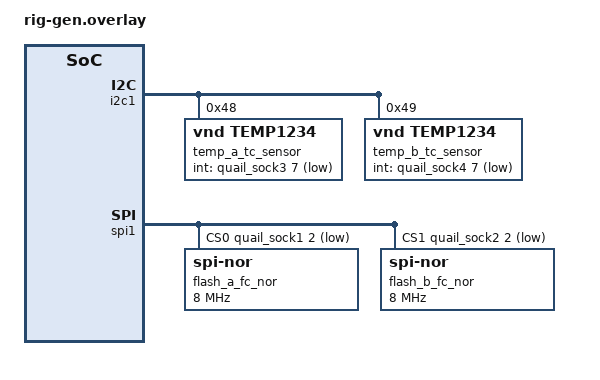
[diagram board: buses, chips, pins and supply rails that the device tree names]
/* generated by rigexp — do not edit; the rig file is the source of truth (R3)
 * rig: quail_temp_farm  board: mikroe_quail/stm32f427xx/rig
 */

&i2c1 {
	temp_a_tc_sensor: sensor@48 {
		compatible = "vnd,temp1234";
		reg = <0x48>;
		int-gpios = <&quail_sock3 7 0x1>;	/* INT */
		status = "okay";
	};
	temp_b_tc_sensor: sensor@49 {
		compatible = "vnd,temp1234";
		reg = <0x49>;
		int-gpios = <&quail_sock4 7 0x1>;	/* INT */
		status = "okay";
	};
};

&spi1 {
	cs-gpios = <&quail_sock1 2 1 /* ACTIVE_LOW */>, <&quail_sock2 2 1 /* ACTIVE_LOW */>;
	flash_a_fc_nor: nor@0 {
		compatible = "jedec,spi-nor";
		spi-max-frequency = <8000000>;
		jedec-id = [c8 40 15];
		size = <4194304>;
		reg = <0>;
		status = "okay";
	};
	flash_b_fc_nor: nor@1 {
		compatible = "jedec,spi-nor";
		spi-max-frequency = <8000000>;
		jedec-id = [c8 40 15];
		size = <4194304>;
		reg = <1>;
		status = "okay";
	};
};
